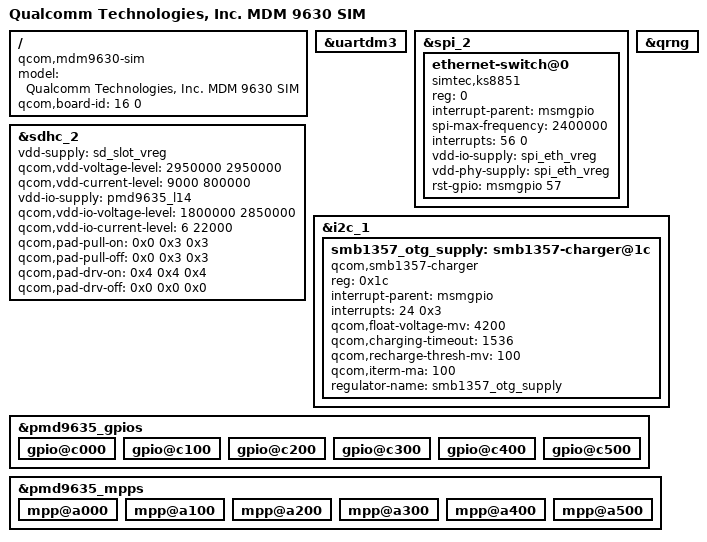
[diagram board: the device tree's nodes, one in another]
/* Copyright (c) 2013-2014, The Linux Foundation. All rights reserved.
 *
 * This program is free software; you can redistribute it and/or modify
 * it under the terms of the GNU General Public License version 2 and
 * only version 2 as published by the Free Software Foundation.
 *
 * This program is distributed in the hope that it will be useful,
 * but WITHOUT ANY WARRANTY; without even the implied warranty of
 * MERCHANTABILITY or FITNESS FOR A PARTICULAR PURPOSE.  See the
 * GNU General Public License for more details.
 */

/dts-v1/;

#include "mdm9630.dtsi"

/ {
	model = "Qualcomm Technologies, Inc. MDM 9630 SIM";
	compatible = "qcom,mdm9630-sim", "qcom,mdm9630", "qcom,sim";
	qcom,board-id = <16 0>;
};

&uartdm3{
	status = "ok";
};

&spi_2 {
	ethernet-switch@0 {
		compatible = "simtec,ks8851";
		reg = <0>;
		interrupt-parent = <&msmgpio>;
		spi-max-frequency = <2400000>;
		interrupts = <56 0>;
		vdd-io-supply = <&spi_eth_vreg>;
		vdd-phy-supply = <&spi_eth_vreg>;
		rst-gpio = <&msmgpio 57 0>;
	};
};

&qrng {
	status = "okay";
};

&sdhc_2 {
	vdd-supply = <&sd_slot_vreg>;
	qcom,vdd-voltage-level = <2950000 2950000>;
	qcom,vdd-current-level = <9000 800000>;

	vdd-io-supply = <&pmd9635_l14>;
	qcom,vdd-io-voltage-level = <1800000 2850000>;
	qcom,vdd-io-current-level = <6 22000>;

	qcom,pad-pull-on = <0x0 0x3 0x3>; /* no-pull, pull-up, pull-up */
	qcom,pad-pull-off = <0x0 0x3 0x3>; /* no-pull, pull-up, pull-up */
	qcom,pad-drv-on = <0x4 0x4 0x4>; /* 10mA, 10mA, 10mA */
	qcom,pad-drv-off = <0x0 0x0 0x0>; /* 2mA, 2mA, 2mA */
	status = "ok";
};

&i2c_1 {
	smb1357_otg_supply: smb1357-charger@1c {
		compatible = "qcom,smb1357-charger";
		reg = <0x1c>;
		interrupt-parent = <&msmgpio>;
		interrupts = <24 0x3>;	/* MDM GPIO 24 */
		qcom,float-voltage-mv = <4200>;
		qcom,charging-timeout = <1536>;
		qcom,recharge-thresh-mv = <100>;
		qcom,iterm-ma = <100>;
		regulator-name = "smb1357_otg_supply";
	};
};

&pmd9635_gpios {
	gpio@c000 { /* GPIO 1 */
	};

	gpio@c100 { /* GPIO 2 */
	};

	gpio@c200 { /* GPIO 3 */
		status = "ok";
	};

	gpio@c300 { /* GPIO 4 */
		status = "ok";
	};

	gpio@c400 { /* GPIO 5 */
	};

	gpio@c500 { /* GPIO 6 */
	};
};

&pmd9635_mpps {
	mpp@a000 { /* MPP 1 */
		status = "ok";
	};

	mpp@a100 { /* MPP 2 */
		status = "ok";
	};

	mpp@a200 { /* MPP 3 */
		status = "ok";
	};

	mpp@a300 { /* MPP 4 */
		status = "ok";
	};

	mpp@a400 { /* MPP 5 */
	};

	mpp@a500 { /* MPP 6 */
		status = "ok";
	};
};
